# PIC32CK2051SG01100 device description
Architecture: CORTEX-M33; Family: PIC32CK; Series: PIC32CKSG01
Registers are 32-bit, read-write, reset 0x0 unless marked. A register's access mark holds for its fields unless they carry their own. Offsets are from the block's base; [hi:lo] are bit positions; {n}, {i} and the like mark numbered series; 'fields as' and 'values as' point back to an identical list.

## MCLK — Main Clock
Instances: MCLK 0x44012000
0x00 INTENCLR (atomic clear) — Interrupt Enable Clear
  [0] CKRDY — Clock Ready Interrupt Enable
0x04 INTENSET (atomic set) — Interrupt Enable Set
  [0] CKRDY — Clock Ready Interrupt Enable
0x08 INTFLAG reset 0x1 (atomic clear) — Interrupt Flag Status and Clear
  [0] CKRDY — Clock Ready
0x0C CLKDIV — Clock Divider Control
  [7:0] DIV — Clock Domain Division Factor
    1=Divide by 1; 2=Divide by 2; 4=Divide by 4; 8=Divide by 8; 16=Divide by 16; 32=Divide by 32; 64=Divide by 64; 128=Divide by 128
{0x3C+4i} CLKMSK[{i}] (i=0..8) — Peripheral Clock Enable Mask
  [31:0] MASK

## MPU — Memory Protection Unit
Instances: MPU 0xE000ED90, MPU_NS 0xE002ED90
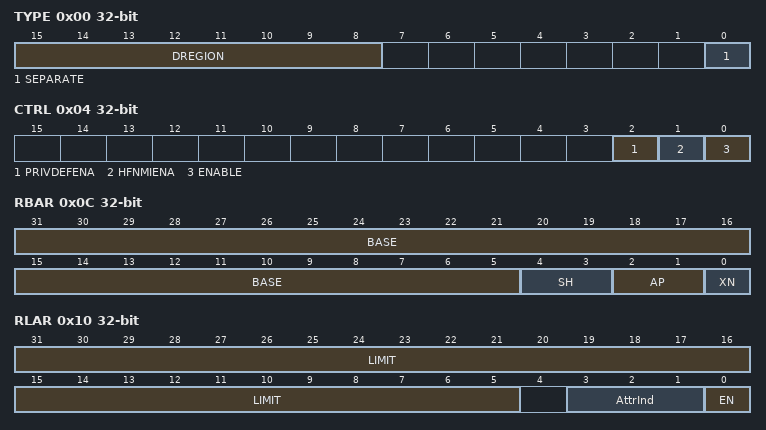
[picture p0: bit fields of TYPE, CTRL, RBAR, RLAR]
0x00 TYPE ro reset not defined — MPU Type Register
  [15:8] DREGION — Number of MPU data regions
  [0] SEPARATE — Separate instructions and data address regions
0x04 CTRL reset not defined — MPU Control Register
  [2] PRIVDEFENA — Privileged default enable
  [1] HFNMIENA — HardFault, NMI enable
  [0] ENABLE — MPU enable
0x08 RNR reset not defined — MPU Region Number Register
  [7:0] REGION — Selected region number
0x0C RBAR reset not defined — MPU Region Base Address Register
  [31:5] BASE — Base address
  [4:3] SH — Shareability
    0=NO (Non-shareable); 2=OUTER (Outer shareable); 3=INNER (Inner shareable)
  [2:1] AP — Access permissions
    0=RWPRIV (Read/write by privileged code only); 1=RWANY (Read/write by any privilege level); 2=RPRIV (Read-only by privileged code only); 3=RANY (Read-only by any privilege level)
  [0] XN — Execute Never
0x10 RLAR reset not defined — MPU Region Limit Address Register
  [31:5] LIMIT — Limit address
  [3:1] AttrInd — Attribute Index
  [0] EN — Region enable
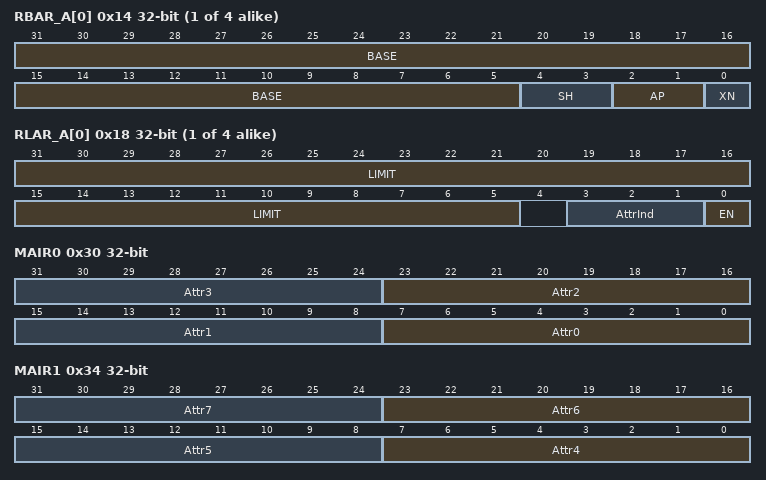
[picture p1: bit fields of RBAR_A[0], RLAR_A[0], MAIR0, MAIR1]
{0x14+4i} RBAR_A[{i}] (i=0..3) reset not defined — MPU Region Base Address Register Alias x
  fields as RBAR
{0x18+4i} RLAR_A[{i}] (i=0..3) reset not defined — MPU Region Limit Address Register Alias x
  fields as RLAR
0x30 MAIR0 reset not defined — MPU Memory Attribute Indirection Register 0
  [8n+7:8n] Attr{n} (n=0..3) — Attribute of MPU region {n}
0x34 MAIR1 reset not defined — MPU Memory Attribute Indirection Register 1
  [8n-25:8n-32] Attr{n} (n=4..7) — Attribute of MPU region {n}

## NVIC — Nested Vectored Interrupt Controller
Instances: NVIC 0xE000E100, NVIC_NS 0xE002E100
{0x0+4i} ISER[{i}] (i=0..4) reset not defined — Interrupt Set Enable Register n
  [31:0] SETENA — Set enable
{0x80+4i} ICER[{i}] (i=0..4) reset not defined — Interrupt Clear Enable Register n
  [31:0] CLRENA — Clear enable
{0x100+4i} ISPR[{i}] (i=0..4) reset not defined — Interrupt Set Pending Register n
  [31:0] SETPEND — Set pending
{0x180+4i} ICPR[{i}] (i=0..4) reset not defined — Interrupt Clear Pending Register n
  [31:0] CLRPEND — Clear pending
{0x200+4i} IABR[{i}] (i=0..4) ro reset not defined — Interrupt Active Bit Register n
  [31:0] ACTIVE — Active state
{0x280+4i} ITNS[{i}] (i=0..4) reset not defined — Interrupt Target Non-secure Register n
  [31:0] ITNS — Interrupt Targets Non-secure
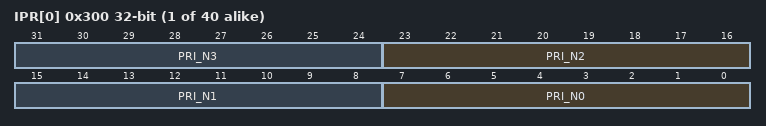
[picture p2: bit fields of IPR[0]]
{0x300+4i} IPR[{i}] (i=0..39) reset not defined — Interrupt Priority Register n
  [8n+7:8n] PRI_N{n} (n=0..3) — Priority of interrupt number 4n+{n}
0xE00 STIR wo reset not defined — Software Triggered Interrupt Register
  [8:0] INTID — Interrupt ID of the interrupt to trigger, in the range 0-479. For example, a value of 0x03 specifies interrupt IRQ3.

## OSC32KCTRL — 32kHz Oscillators Control
Instances: OSC32KCTRL 0x4400E000
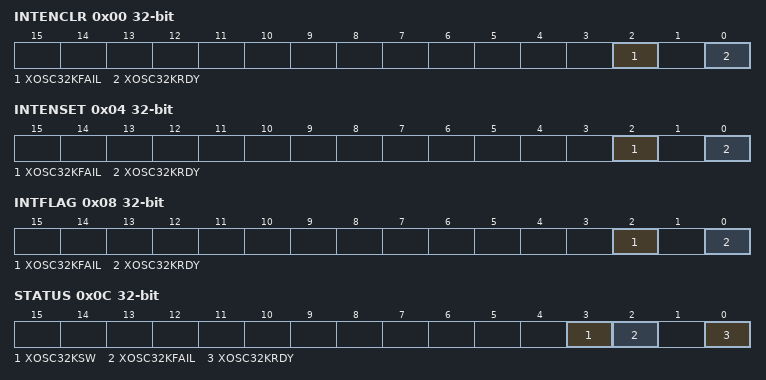
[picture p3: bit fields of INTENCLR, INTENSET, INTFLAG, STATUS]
0x00 INTENCLR (atomic clear) — Interrupt Enable Clear
  [2] XOSC32KFAIL — XOSC32K Clock Failure Detector Interrupt Enable
  [0] XOSC32KRDY — XOSC32K Ready Interrupt Enable
0x04 INTENSET (atomic set) — Interrupt Enable Set
  fields as INTENCLR
0x08 INTFLAG (atomic clear) — Interrupt Flag Status and Clear
  [2] XOSC32KFAIL — XOSC32K Clock Failure Detector
  [0] XOSC32KRDY — XOSC32K Ready
0x0C STATUS ro — Power and Clocks Status
  [3] XOSC32KSW — XOSC32K Clock switch
  [2] XOSC32KFAIL — XOSC32K Clock Failure Detector
  [0] XOSC32KRDY — XOSC32K Ready
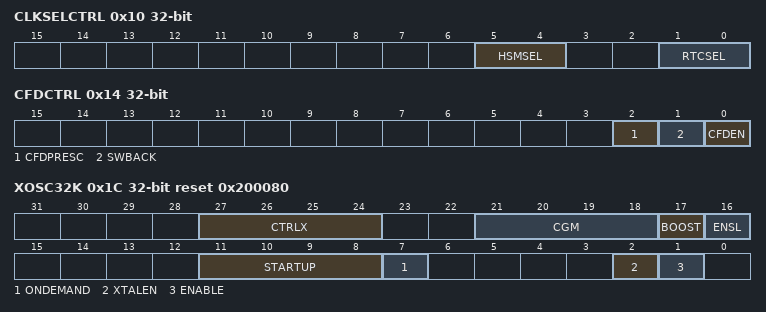
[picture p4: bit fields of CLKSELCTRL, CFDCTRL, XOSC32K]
0x10 CLKSELCTRL — Clock Selection Control
  [5:4] HSMSEL — HSM Clock Selection
    0=ULP32K (32.768kHz from 32kHz internal ULP oscillator); 2=XOSC32K (32.768kHz from 32.768kHz external crystal oscillator)
  [1:0] RTCSEL — RTC Clock Selection
    0=ULP32K (32.768kHz from 32kHz internal ULP oscillator); 1=ULP1K (1.024kHz from 32kHz internal ULP oscillator); 2=XOSC32K (32.768kHz from 32.768kHz external crystal oscillator); 3=XOSC1K (1.024kHz from 32.768kHz internal oscillator)
0x14 CFDCTRL — Clock Failure Detector Control
  [2] CFDPRESC — Clock Failure Detector Prescaler
  [1] SWBACK — Clock Switch Back
  [0] CFDEN — Clock Failure Detector Enable
0x18 EVCTRL — Event Control
  [0] CFDEO — Clock Failure Detector Event Output Enable
0x1C XOSC32K reset 0x200080 — 32kHz External Crystal Oscillator (XOSC32K) Control
  [27:24] CTRLX — Extended Control
  [21:18] CGM — Control Gain Mode
    0=The lower Control Gain Mode value; {v}=A higher Control Gain Mode value than CGM{v-1} (v=1..14); 15=The highest Control Gain Mode value
  [17] BOOST — Gain Boost
  [16] ENSL — Enable Servo Loop
  [11:8] STARTUP — Startup Mode
    0=1CYCLE (1 ULP clock cycle); 1=16CYCLES (16 ULP clock cycles); 2=32CYCLES (32 ULP clock cycles); 3=2048CYCLES (2048 ULP clock cycles); 4=4096CYCLES (4096 ULP clock cycles); 5=8192CYCLES (8192 ULP clock cycles); 6=16384CYCLES (16384 ULP clock cycles); 7=32768CYCLES (32768 ULP clock cycles); 8=65536CYCLES (65536 ULP clock cycles); 9=131072CYCLES (131072 ULP clock cycles); 10=262144CYCLES (262144 ULP clock cycles)
  [7] ONDEMAND — On Demand Mode
  [2] XTALEN — Crystal Oscillator Enable
  [1] ENABLE — Oscillator Enable

## Notices in the file
Copyright (c) 2021 Microchip Technology Inc.
SPDX-License-Identifier: Apache-2.0
Licensed under the Apache License, Version 2.0 (the "License");
you may not use this file except in compliance with the License.
You may obtain a copy of the License at
http://www.apache.org/licenses/LICENSE-2.0
Unless required by applicable law or agreed to in writing, software
distributed under the License is distributed on an "AS IS" BASIS,
WITHOUT WARRANTIES OR CONDITIONS OF ANY KIND, either express or implied.
See the License for the specific language governing permissions and
limitations under the License.
